# SRAMCTRL register map
Vendor: Texas Instruments
Peripheral module from a debugger description file (folder UCD3138R064RJA).
Registers are 32-bit, read-write, no defined reset value unless marked. A register's access mark holds for its fields unless they carry their own. Offsets are as the file gives them; lines under a group give offsets from that group; [hi:lo] are bit positions; {n}, {i} and the like mark numbered series; 'fields as' and 'values as' point back to an identical list; <NAME> marks a mode.

## SRAMCTRL — This is top module of SRAM Controller for UCD
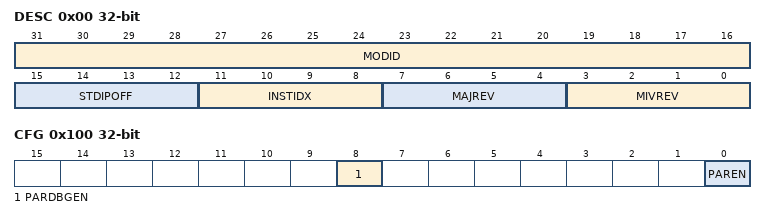
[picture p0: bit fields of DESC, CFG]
0x00 DESC ro — This register identifies the peripheral
  [31:16] MODID — Module identifier
  [15:12] STDIPOFF — 64 B Standard IP MMR block<br>0: STDIP MMRs do not exist<br>1:15: These MMRs begin at offset 64*STDIPOFF from IP base address
  [11:8] INSTIDX — IP Instance number
  [7:4] MAJREV — Major revision
  [3:0] MIVREV — Minor revision
0x64 DTB — This bit field is used to select DTB mux digital inputs
  [1:0] SEL — DTB Selection
0x100 CFG — Configuration Register
  [8] PARDBGEN — SRAM Parity Debug Enable.
    0=DISABLE (Disable Parity Debug. Normal operation); 1=ENABLE (Enable Parity Debug. An address offset can be written to [PARDBG.ADDR] and parity errors will be generated on reads from within this offset)
  [0] PAREN — SRAM Parity Enable.
    0=DISABLE (Disable Parity); 1=ENABLE (Enable Parity)
0x104 INITSEL — Initilizataion Select Register.
  [0] SEL — Bank Select
0x108 INITTRIG — Initilizataion Trigger Register.
  [0] TRIG — Trigger Initilization. This bit will auto clear once initlization is complete
0x10C INITSTAT ro — Initilizataion Status
  [0] BUSY — Indicate that bank is getting initialzed
0x110 PARDBG — Parity error check debug address setting
  [19:2] ADDR — Debug Parity Error Address Offset. When [CFG.PARDBGEN] is 1, this field is used to set a parity debug address offset. Writes within this address offset will force incorrect parity bits to be stored together with the data written. The following reads within this same address offset will thus result in parity errors to be generated.
0x114 PARERR ro — Parity error
  [31:0] PARERR — Parity Error Address Offset. This holds the address offset that first generated the parity error and an interrupt is generated. This register is 'Clear-On-Read'
